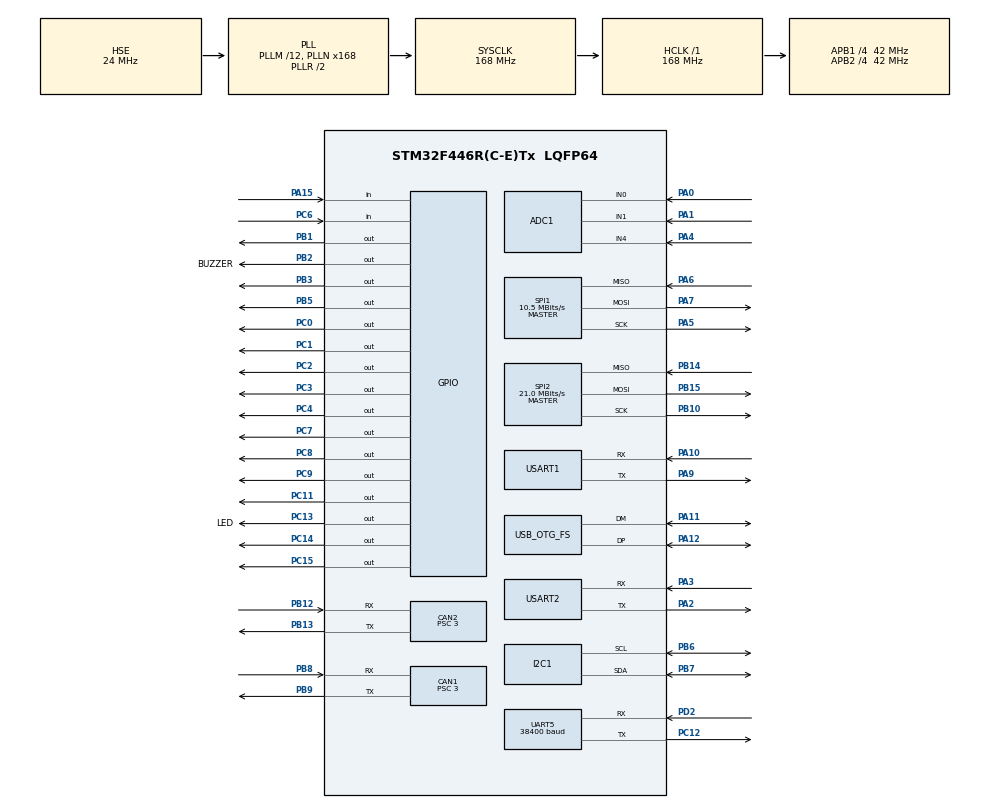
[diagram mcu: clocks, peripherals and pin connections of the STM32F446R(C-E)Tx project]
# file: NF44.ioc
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ADC1.Channel-0\#ChannelRegularConversion=ADC_CHANNEL_0
ADC1.NbrOfConversionFlag=1
ADC1.Rank-0\#ChannelRegularConversion=1
ADC1.SamplingTime-0\#ChannelRegularConversion=ADC_SAMPLETIME_3CYCLES
ADC1.master=1
CAN1.ABOM=ENABLE
CAN1.BS1=CAN_BS1_10TQ
CAN1.BS2=CAN_BS2_3TQ
CAN1.CalculateBaudRate=1000000
CAN1.CalculateTimeBit=1000
CAN1.CalculateTimeQuantum=71.42857142857143
CAN1.Prescaler=3
CAN2.ABOM=ENABLE
CAN2.BS1=CAN_BS1_10TQ
CAN2.BS2=CAN_BS2_3TQ
CAN2.CalculateBaudRate=1000000
CAN2.CalculateTimeBit=1000
CAN2.CalculateTimeQuantum=71.42857142857143
CAN2.Mode=CAN_MODE_NORMAL
CAN2.Prescaler=3
Dma.Request0=USART1_RX
Dma.Request1=USART2_RX
Dma.Request2=UART5_RX
Dma.UART5_RX.2.Direction=DMA_PERIPH_TO_MEMORY
Dma.UART5_RX.2.FIFOMode=DMA_FIFOMODE_DISABLE
Dma.UART5_RX.2.Instance=DMA1_Stream0
Dma.UART5_RX.2.MemDataAlignment=DMA_MDATAALIGN_BYTE
Dma.UART5_RX.2.MemInc=DMA_MINC_ENABLE
Dma.UART5_RX.2.Mode=DMA_NORMAL
Dma.UART5_RX.2.PeriphDataAlignment=DMA_PDATAALIGN_BYTE
Dma.UART5_RX.2.PeriphInc=DMA_PINC_DISABLE
Dma.UART5_RX.2.Priority=DMA_PRIORITY_LOW
Dma.USART1_RX.0.Direction=DMA_PERIPH_TO_MEMORY
Dma.USART1_RX.0.FIFOMode=DMA_FIFOMODE_DISABLE
Dma.USART1_RX.0.Instance=DMA2_Stream2
Dma.USART1_RX.0.MemDataAlignment=DMA_MDATAALIGN_BYTE
Dma.USART1_RX.0.MemInc=DMA_MINC_ENABLE
Dma.USART1_RX.0.Mode=DMA_NORMAL
Dma.USART1_RX.0.PeriphDataAlignment=DMA_PDATAALIGN_BYTE
Dma.USART1_RX.0.PeriphInc=DMA_PINC_DISABLE
Dma.USART1_RX.0.Priority=DMA_PRIORITY_LOW
Dma.USART2_RX.1.Direction=DMA_PERIPH_TO_MEMORY
Dma.USART2_RX.1.FIFOMode=DMA_FIFOMODE_DISABLE
Dma.USART2_RX.1.Instance=DMA1_Stream5
Dma.USART2_RX.1.MemDataAlignment=DMA_MDATAALIGN_BYTE
Dma.USART2_RX.1.MemInc=DMA_MINC_ENABLE
Dma.USART2_RX.1.Mode=DMA_NORMAL
Dma.USART2_RX.1.PeriphDataAlignment=DMA_PDATAALIGN_BYTE
Dma.USART2_RX.1.PeriphInc=DMA_PINC_DISABLE
Dma.USART2_RX.1.Priority=DMA_PRIORITY_LOW
FREERTOS.Tasks01=defaultTask,0,128,StartDefaultTask,Default,NULL,Dynamic,NULL,NULL
FREERTOS.configENABLE_FPU=1
FREERTOS.configTOTAL_HEAP_SIZE=0x12000
FREERTOS.configUSE_NEWLIB_REENTRANT=1
Mcu.Family=STM32F4
Mcu.Name=STM32F446R(C-E)Tx
Mcu.Package=LQFP64
NVIC.CAN1_RX0_IRQn=true\:5\:0\:false\:false\:true\:true\:true\:true\:true
NVIC.CAN2_RX0_IRQn=true\:5\:0\:false\:false\:true\:true\:true\:true\:true
NVIC.DMA1_Stream0_IRQn=true\:5\:0\:false\:false\:true\:true\:false\:true\:true
NVIC.DMA1_Stream5_IRQn=true\:5\:0\:false\:false\:true\:true\:false\:true\:true
NVIC.DMA2_Stream2_IRQn=true\:5\:0\:false\:false\:true\:true\:false\:true\:true
NVIC.OTG_FS_IRQn=true\:5\:0\:false\:false\:true\:true\:true\:true\:true
NVIC.PriorityGroup=NVIC_PRIORITYGROUP_4
NVIC.TIM4_IRQn=true\:15\:0\:false\:false\:true\:false\:false\:true\:true
NVIC.TimeBase=TIM4_IRQn
NVIC.TimeBaseIP=TIM4
NVIC.UART5_IRQn=true\:5\:0\:false\:false\:true\:true\:true\:true\:true
NVIC.USART1_IRQn=true\:5\:0\:false\:false\:true\:true\:true\:true\:true
PA0-WKUP.Signal=ADCx_IN0
PA1.Signal=ADCx_IN1
PA10.Mode=Asynchronous
PA10.Signal=USART1_RX
PA11.Mode=Device_Only
PA11.Signal=USB_OTG_FS_DM
PA12.Mode=Device_Only
PA12.Signal=USB_OTG_FS_DP
PA13.Mode=Serial_Wire
PA13.Signal=SYS_JTMS-SWDIO
PA14.Mode=Serial_Wire
PA14.Signal=SYS_JTCK-SWCLK
PA15.Signal=GPIO_Input
PA2.Mode=Asynchronous
PA2.Signal=USART2_TX
PA3.Mode=Asynchronous
PA3.Signal=USART2_RX
PA4.Signal=ADCx_IN4
PA5.Mode=Full_Duplex_Master
PA5.Signal=SPI1_SCK
PA6.Mode=Full_Duplex_Master
PA6.Signal=SPI1_MISO
PA7.Mode=Full_Duplex_Master
PA7.Signal=SPI1_MOSI
PA9.Mode=Asynchronous
PA9.Signal=USART1_TX
PB1.Signal=GPIO_Output
PB10.Mode=Full_Duplex_Master
PB10.Signal=SPI2_SCK
PB12.Mode=CAN_Activate
PB12.Signal=CAN2_RX
PB13.Mode=CAN_Activate
PB13.Signal=CAN2_TX
PB14.Mode=Full_Duplex_Master
PB14.Signal=SPI2_MISO
PB15.Mode=Full_Duplex_Master
PB15.Signal=SPI2_MOSI
PB2.GPIO_Label=BUZZER
PB2.Signal=GPIO_Output
PB3.Signal=GPIO_Output
PB4.Signal=I2C3_SDA
PB5.Signal=GPIO_Output
PB6.Mode=I2C
PB6.Signal=I2C1_SCL
PB7.Mode=I2C
PB7.Signal=I2C1_SDA
PB8.Mode=CAN_Activate
PB8.Signal=CAN1_RX
PB9.Mode=CAN_Activate
PB9.Signal=CAN1_TX
PC0.Signal=GPIO_Output
PC1.Signal=GPIO_Output
PC11.Signal=GPIO_Output
PC12.Mode=Asynchronous
PC12.Signal=UART5_TX
PC13.GPIO_Label=LED
PC13.Signal=GPIO_Output
PC14-OSC32_IN.Signal=GPIO_Output
PC15-OSC32_OUT.Signal=GPIO_Output
PC2.Signal=GPIO_Output
PC3.Signal=GPIO_Output
PC4.PinState=GPIO_PIN_SET
PC4.Signal=GPIO_Output
PC5.Signal=USART3_RX
PC6.GPIO_PuPd=GPIO_PULLUP
PC6.Signal=GPIO_Input
PC7.Signal=GPIO_Output
PC8.Signal=GPIO_Output
PC9.Signal=GPIO_Output
PD2.Mode=Asynchronous
PD2.Signal=UART5_RX
PH0-OSC_IN.Mode=HSE-External-Oscillator
PH0-OSC_IN.Signal=RCC_OSC_IN
PH1-OSC_OUT.Mode=HSE-External-Oscillator
PH1-OSC_OUT.Signal=RCC_OSC_OUT
ProjectManager.HeapSize=0x200
ProjectManager.StackSize=0x400
ProjectManager.TargetToolchain=CMake
RCC.AHBFreq_Value=168000000
RCC.APB1CLKDivider=RCC_HCLK_DIV4
RCC.APB1Freq_Value=42000000
RCC.APB1TimFreq_Value=84000000
RCC.APB2CLKDivider=RCC_HCLK_DIV4
RCC.APB2Freq_Value=42000000
RCC.APB2TimFreq_Value=84000000
RCC.CortexFreq_Value=168000000
RCC.HCLKFreq_Value=168000000
RCC.HSE_VALUE=24000000
RCC.PLLM=12
RCC.PLLN=168
RCC.PLLQ=7
RCC.SYSCLKFreq_VALUE=168000000
RCC.SYSCLKSource=RCC_SYSCLKSOURCE_PLLRCLK
RCC.USBFreq_Value=48000000
RCC.VCOOutputFreq_Value=336000000
SH.ADCx_IN0.0=ADC1_IN0,IN0
SH.ADCx_IN1.0=ADC1_IN1,IN1
SH.ADCx_IN4.0=ADC1_IN4,IN4
SPI1.BaudRatePrescaler=SPI_BAUDRATEPRESCALER_4
SPI1.CalculateBaudRate=10.5 MBits/s
SPI1.Direction=SPI_DIRECTION_2LINES
SPI1.Mode=SPI_MODE_MASTER
SPI1.VirtualType=VM_MASTER
SPI2.BaudRatePrescaler=SPI_BAUDRATEPRESCALER_2
SPI2.CalculateBaudRate=21.0 MBits/s
SPI2.Direction=SPI_DIRECTION_2LINES
SPI2.Mode=SPI_MODE_MASTER
SPI2.VirtualType=VM_MASTER
STMicroelectronics.X-CUBE-ALGOBUILD.1.4.0.LibraryCcDSPOoLibraryJjDSPOoLibrary=true
TIM8.Period=50-1
TIM8.Prescaler=62-1
UART5.BaudRate=38400
UART5.VirtualMode=Asynchronous
UART5.WordLength=WORDLENGTH_8B
USART1.VirtualMode=VM_ASYNC
USART2.VirtualMode=VM_ASYNC
USB_DEVICE.CLASS_NAME_FS=CDC
USB_DEVICE.USBD_MAX_STR_DESC_SIZ-CDC_FS=1024
USB_DEVICE.VirtualMode-CDC_FS=Cdc
USB_DEVICE.VirtualModeFS=Cdc_FS
USB_OTG_FS.VirtualMode=Device_Only
VP_CRC_VS_CRC.Mode=CRC_Activate
VP_FREERTOS_VS_CMSIS_V1.Mode=CMSIS_V1
VP_STMicroelectronics.X-CUBE-ALGOBUILD_VS_DSPOoLibraryJjLibrary_1.4.0_1.4.0.Mode=DSPOoLibraryJjLibrary
VP_SYS_VS_tim4.Mode=TIM4
VP_TIM8_VS_ClockSourceINT.Mode=Internal
VP_USB_DEVICE_VS_USB_DEVICE_CDC_FS.Mode=CDC_FS
board=custom

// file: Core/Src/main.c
/* USER CODE BEGIN Header */
/**
  ******************************************************************************
  * @file           : main.c
  * @brief          : Main program body
  ******************************************************************************
  * @attention
  *
  * Copyright (c) 2025 STMicroelectronics.
  * All rights reserved.
  *
  * This software is licensed under terms that can be found in the LICENSE file
  * in the root directory of this software component.
  * If no LICENSE file comes with this software, it is provided AS-IS.
  *
  ******************************************************************************
  */
/* USER CODE END Header */
#include "main.h"
#include "cmsis_os.h"
#include "adc.h"
#include "can.h"
#include "crc.h"
#include "dma.h"
#include "i2c.h"
#include "spi.h"
#include "tim.h"
#include "usart.h"
#include "usb_device.h"
#include "gpio.h"

/* USER CODE BEGIN Includes */
#include "modules.h"
/* USER CODE END Includes */

void SystemClock_Config(void);
void MX_FREERTOS_Init(void);

int main(void)
{

  /* MCU Configuration--------------------------------------------------------*/

  /* Reset of all peripherals, Initializes the Flash interface and the Systick. */
  HAL_Init();

  /* Configure the system clock */
  SystemClock_Config();

  /* Initialize all configured peripherals */
  MX_GPIO_Init();
  MX_DMA_Init();
  MX_ADC1_Init();
  MX_CAN1_Init();
  MX_CAN2_Init();
  MX_I2C1_Init();
  MX_SPI1_Init();
  MX_SPI2_Init();
  MX_UART5_Init();
  MX_USART1_UART_Init();
  MX_USART2_UART_Init();
  MX_CRC_Init();
  MX_TIM8_Init();
  /* USER CODE BEGIN 2 */

   Modules_Init();  //用户自定义模块初始化

  /* USER CODE END 2 */

  /* Call init function for freertos objects (in cmsis_os2.c) */
  MX_FREERTOS_Init();

  /* Start scheduler */
  osKernelStart();

  /* We should never get here as control is now taken by the scheduler */

  /* Infinite loop */
  while (1)
  {

  }
}

void SystemClock_Config(void)
{
  RCC_OscInitTypeDef RCC_OscInitStruct = {0};
  RCC_ClkInitTypeDef RCC_ClkInitStruct = {0};

  /** Configure the main internal regulator output voltage
  */
  __HAL_RCC_PWR_CLK_ENABLE();
  __HAL_PWR_VOLTAGESCALING_CONFIG(PWR_REGULATOR_VOLTAGE_SCALE1);

  /** Initializes the RCC Oscillators according to the specified parameters
  * in the RCC_OscInitTypeDef structure.
  */
  RCC_OscInitStruct.OscillatorType = RCC_OSCILLATORTYPE_HSE;
  RCC_OscInitStruct.HSEState = RCC_HSE_ON;
  RCC_OscInitStruct.PLL.PLLState = RCC_PLL_ON;
  RCC_OscInitStruct.PLL.PLLSource = RCC_PLLSOURCE_HSE;
  RCC_OscInitStruct.PLL.PLLM = 12;
  RCC_OscInitStruct.PLL.PLLN = 168;
  RCC_OscInitStruct.PLL.PLLP = RCC_PLLP_DIV2;
  RCC_OscInitStruct.PLL.PLLQ = 7;
  RCC_OscInitStruct.PLL.PLLR = 2;
  if (HAL_RCC_OscConfig(&RCC_OscInitStruct) != HAL_OK)
  {
    Error_Handler();
  }

  /** Initializes the CPU, AHB and APB buses clocks
  */
  RCC_ClkInitStruct.ClockType = RCC_CLOCKTYPE_HCLK|RCC_CLOCKTYPE_SYSCLK
                              |RCC_CLOCKTYPE_PCLK1|RCC_CLOCKTYPE_PCLK2;
  RCC_ClkInitStruct.SYSCLKSource = RCC_SYSCLKSOURCE_PLLRCLK;
  RCC_ClkInitStruct.AHBCLKDivider = RCC_SYSCLK_DIV1;
  RCC_ClkInitStruct.APB1CLKDivider = RCC_HCLK_DIV4;
  RCC_ClkInitStruct.APB2CLKDivider = RCC_HCLK_DIV4;

  if (HAL_RCC_ClockConfig(&RCC_ClkInitStruct, FLASH_LATENCY_5) != HAL_OK)
  {
    Error_Handler();
  }
}

void HAL_TIM_PeriodElapsedCallback(TIM_HandleTypeDef *htim)
{
  if (htim->Instance == TIM4)
  {
    HAL_IncTick();
  }
}

void Error_Handler(void)
{
  __disable_irq();
  while (1)
  {
  }
}
